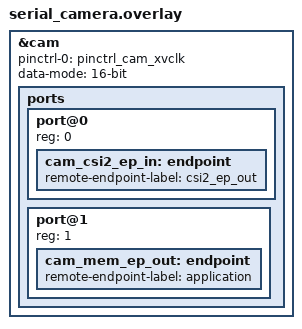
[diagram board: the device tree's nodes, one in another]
&cam {
	status = "okay";

	pinctrl-0 = <&pinctrl_cam_xvclk>;
	pinctrl-names = "default";

	data-mode = "16-bit";

	ports {
		#address-cells = <1>;
		#size-cells = <0>;

		/* MIPI CSI-2 bus endpoint. */
		port@0 {
			reg = <0>;
			cam_csi2_ep_in: endpoint {
				remote-endpoint-label = "csi2_ep_out";
			};
		};

		/* Video buffer output endpoint. */
		port@1 {
			reg = <1>;
			cam_mem_ep_out: endpoint {
				remote-endpoint-label = "application";
			};
		};
	};
};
